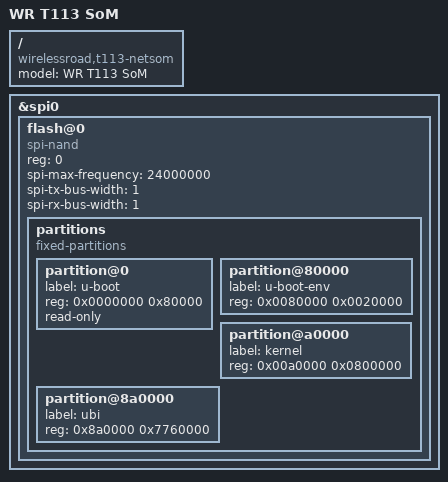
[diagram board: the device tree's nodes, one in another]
// SPDX-License-Identifier: (GPL-2.0+ OR MIT)
// Copyright (C) 2024 WirelessRoad.

/dts-v1/;

#include "sun8i-t113s-wr-netsom.dtsi"

/ {
	model = "WR T113 SoM";
	compatible = "wirelessroad,t113-netsom", "allwinner,sun8i-t113s";
};

&spi0 {
    flash@0 {
        compatible = "spi-nand";
        reg = <0>;
        spi-max-frequency = <24000000>;
        spi-tx-bus-width = <1>;
        spi-rx-bus-width = <1>;
        partitions {
            compatible = "fixed-partitions";
            #address-cells = <1>;
            #size-cells = <1>;
            partition@0 {
                label = "u-boot";
                reg = <0x0000000 0x80000>;
                read-only;
            };
            partition@80000 {
                label = "u-boot-env";
                reg = <0x0080000 0x0020000>;
            };
            partition@a0000 {
                label = "kernel";
                reg = <0x00a0000 0x0800000>;
            };
            partition@8a0000 {
                label = "ubi";
                reg = <0x8a0000 0x7760000>;
            };
        };
    };
};
